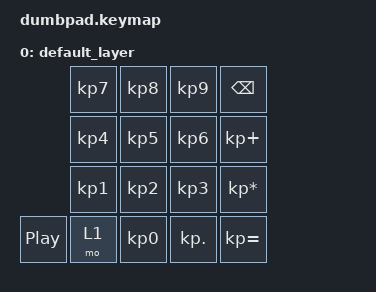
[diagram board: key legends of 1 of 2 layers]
/*
 * Copyright (c) 2022 The ZMK Contributors
 *
 * SPDX-License-Identifier: MIT
 */

#include <behaviors.dtsi>
#include <dt-bindings/zmk/bt.h>
#include <dt-bindings/zmk/keys.h>

/ {
    keymap {
        compatible = "zmk,keymap";

        default_layer {
            bindings = <
                            &kp KP_N7    &kp KP_N8       &kp KP_N9         &kp BSPC
                            &kp KP_N4    &kp KP_N5       &kp KP_N6         &kp KP_PLUS
                            &kp KP_N1    &kp KP_N2       &kp KP_N3         &kp KP_MULTIPLY
                &kp C_PP    &mo 1        &kp KP_N0       &kp KP_DOT        &kp KP_EQUAL
            >;
        };

        encoder_rotate: encoder_rotate {
            compatible = "zmk,encoder-rotate";
            bindings = <&kp &kp VOL_UP &kp &kp VOL_DOWN>;
        };
    };
};

